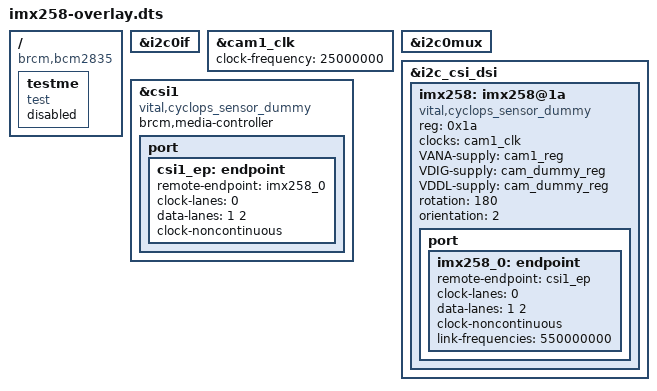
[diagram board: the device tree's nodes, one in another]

// Definitions for "IMX258 camera module" on VC I2C bus
/dts-v1/;
/plugin/;

#include <dt-bindings/gpio/gpio.h>

/ {
	compatible = "brcm,bcm2835";

	fragment@200 {
		target-path = "/";
		__overlay__ {
      testme {
			  compatible = "test";
			  status = "disabled";
      };
    };
	};

	fragment@0 {
		target = <&i2c0if>;
		__overlay__ {
			status = "okay";
		};
	};

	clk_frag: fragment@1 {
		target = <&cam1_clk>;
		__overlay__ {
			status = "okay";
			clock-frequency = <25000000>;
		};
	};

	fragment@2 {
		target = <&i2c0mux>;
		__overlay__ {
			status = "okay";
		};
	};

	i2c_frag: fragment@100 {
		target = <&i2c_csi_dsi>;
		__overlay__ {
			#address-cells = <1>;
			#size-cells = <0>;
			status = "okay";

			imx258: imx258@1a {
				compatible = "vital,cyclops_sensor_dummy";
				reg = <0x1a>;
				status = "okay";

				clocks = <&cam1_clk>;
				clock-names = "xclk";

				VANA-supply = <&cam1_reg>;	/* 2.8v */
				VDIG-supply = <&cam_dummy_reg>;	/* 1.8v */
				VDDL-supply = <&cam_dummy_reg>;	/* 1.2v */

				rotation = <180>;
				orientation = <2>;

				port {
					imx258_0: endpoint {
						remote-endpoint = <&csi1_ep>;
						clock-lanes = <0>;
						data-lanes = <1 2>;
						clock-noncontinuous;
						link-frequencies = /bits/ 64 <550000000>;
					};
				};
			};
		};
	};

	csi_frag: fragment@101 {
		target = <&csi1>;
		__overlay__ {
			status = "okay";
			compatible = "vital,cyclops_sensor_dummy";
			brcm,media-controller;

			port {
				csi1_ep: endpoint {
					remote-endpoint = <&imx258_0>;
					clock-lanes = <0>;
					data-lanes = <1 2>;
					clock-noncontinuous;
				};
			};
		};
	};

	__overrides__ {
		rotation = <&imx258>,"rotation:0";
		orientation = <&imx258>,"orientation:0";
		media-controller = <&csi>,"brcm,media-controller?";
		cam0 = <&i2c_frag>, "target:0=",<&i2c_vc>,
           <&csi_frag>, "target:0=",<&csi0>,
           <&clk_frag>, "target:0=",<&cam0_clk>,
           <&imx258>, "clocks:0=",<&cam0_clk>,
           <&imx258>, "VANA-supply:0=",<&cam0_reg>;
	};
};
